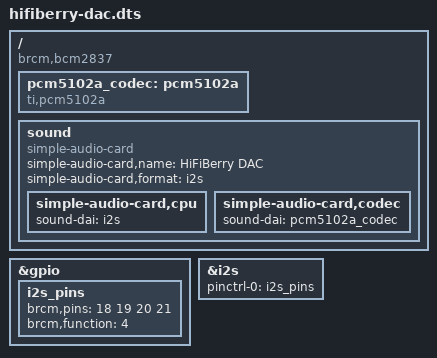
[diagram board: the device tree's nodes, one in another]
/dts-v1/;
/plugin/;

/ {
    compatible = "brcm,bcm2837";

    fragment@0 {
        target = <&gpio>;
        __overlay__ {
            i2s_pins: i2s_pins {
                brcm,pins = <18 19 20 21>;
                brcm,function = <4>;
            };
        };
    };

    fragment@1 {
        target = <&i2s>;
        __overlay__ {
            #sound-dai-cells = <0>;
            pinctrl-names = "default";
            pinctrl-0 = <&i2s_pins>;
            status = "okay";
        };
    };

    fragment@2 {
        target-path = "/";
        __overlay__ {
            pcm5102a_codec: pcm5102a {
                compatible = "ti,pcm5102a";
                #sound-dai-cells = <0>;
            };

            sound {
                compatible = "simple-audio-card";
                simple-audio-card,name = "HiFiBerry DAC";
                simple-audio-card,format = "i2s";

                simple-audio-card,cpu {
                    sound-dai = <&i2s>;
                };

                simple-audio-card,codec {
                    sound-dai = <&pcm5102a_codec>;
                };
            };
        };
    };
};
